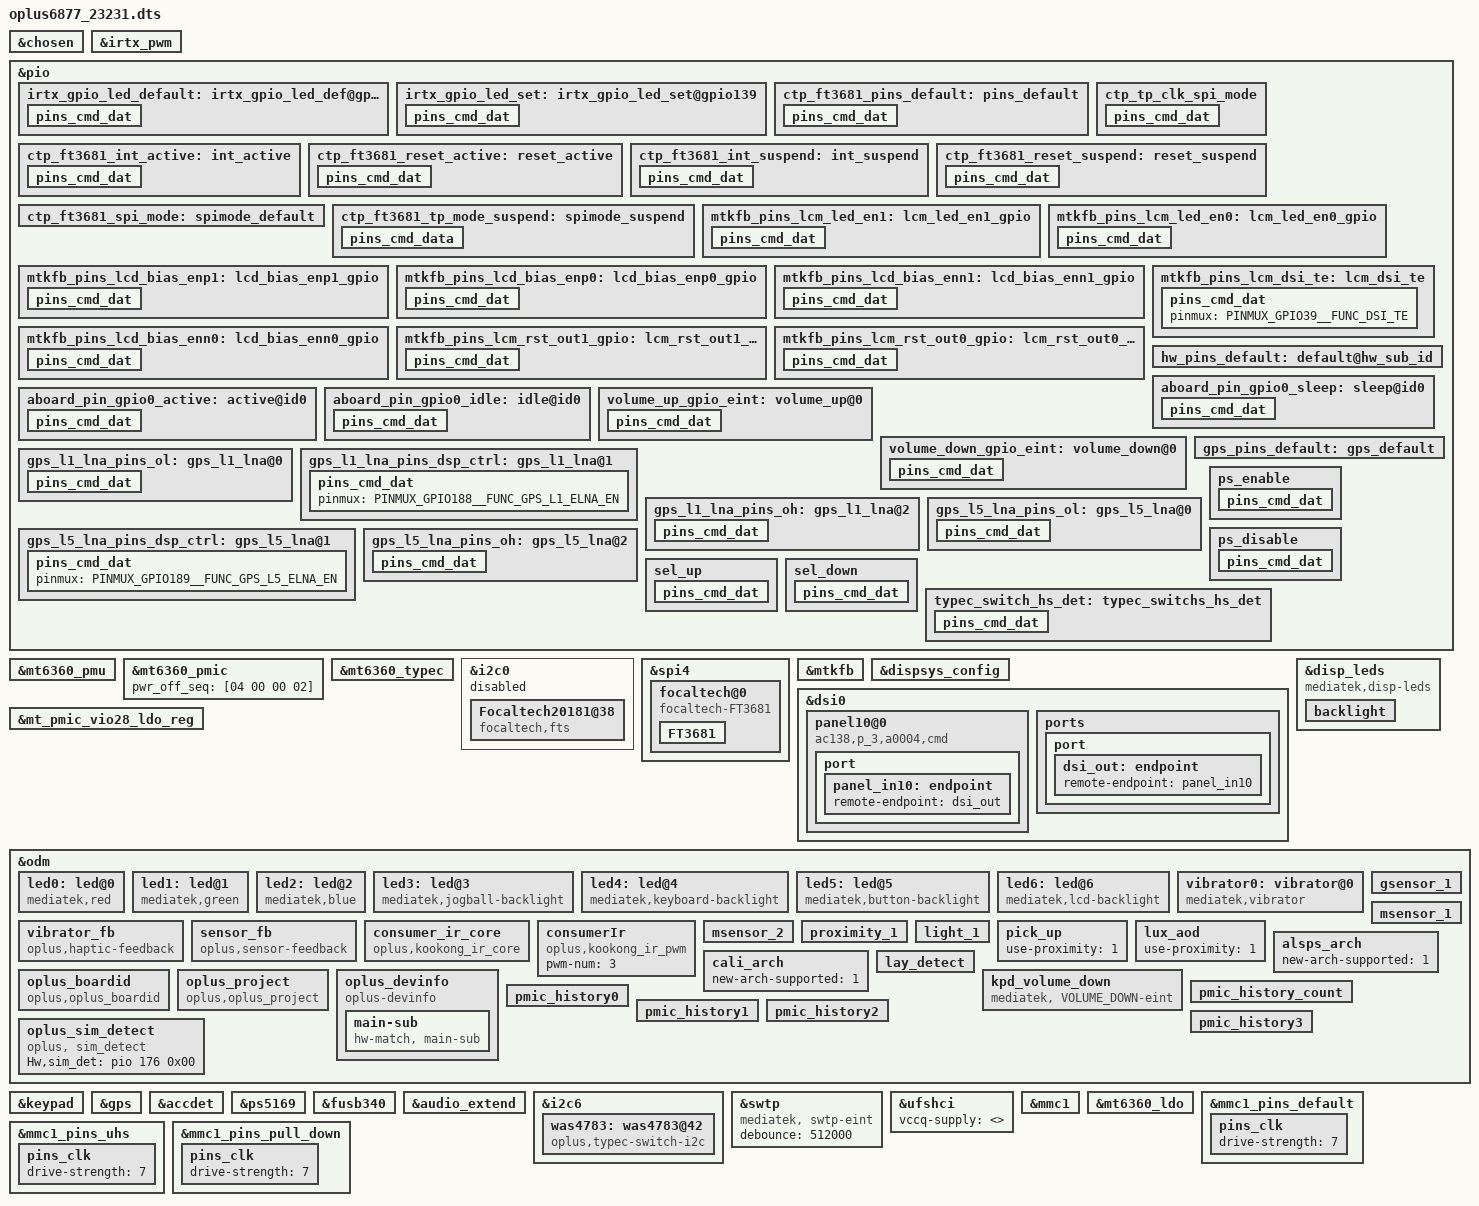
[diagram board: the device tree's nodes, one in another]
// SPDX-License-Identifier: GPL-2.0
/*
 * Copyright (c) 2021 MediaTek Inc.
 */

/dts-v1/;
/plugin/;
#include <dt-bindings/interrupt-controller/irq.h>
#include <dt-bindings/interrupt-controller/arm-gic.h>
#include <dt-bindings/pinctrl/mt6877-pinfunc.h>
#include <dt-bindings/mmc/mt6877-msdc.h>

/* #ifdef CONFIG_UFF_FINGERPRINT */
#include "mediatek/oplus_uff_23231.dtsi"
/* #endif CONFIG_UFF_FINGERPRINT */

/* chosen */
&chosen {
	atag,videolfb-fb_base_l = <0x7e605000>;
	atag,videolfb-fb_base_h = <0x0>;
	atag,videolfb-islcmfound = <1>;
	atag,videolfb-islcm_inited = <0>;
	atag,videolfb-fps= <6000>;
	atag,videolfb-vramSize= <0x1be0000>;
	atag,videolfb-lcmname=
		"td4330_fhdp_dsi_cmd_auo_rt4831_drv";
};

/* IRTX GPIO Start */
&irtx_pwm {
	pinctrl-names = "irtx_gpio_led_default", "irtx_gpio_led_set";
	pinctrl-0 = <&irtx_gpio_led_default>;
	pinctrl-1 = <&irtx_gpio_led_set>;
	status = "okay";
};
&pio {
	/* IRTX GPIO Settings -Start */
	/* default: GPIO0, output, high */
	irtx_gpio_led_default:irtx_gpio_led_def@gpio139 {
		pins_cmd_dat {
			pinmux = <PINMUX_GPIO139__FUNC_GPIO139>;
			slew-rate = <1>;
			bias-disable;
			output-low;
			input-schmitt-enable = <0>;
		};
	};

	irtx_gpio_led_set:irtx_gpio_led_set@gpio139 {
		pins_cmd_dat {
			pinmux = <PINMUX_GPIO139__FUNC_PWM_1>;
			slew-rate = <1>;
			output-high;
		};
	};
}; /* IRTX GPIO Settings -End */

&mt6360_pmu {
	mt6360,intr_gpio_num = <4>; /* direct defined GPIO num */
	mt6360,intr_gpio = <&pio 4 0x0>;
};

&mt6360_pmic {
	pwr_off_seq = [04 00 00 02];
};

&mt6360_typec {
	mt6360pd,intr_gpio_num = <5>; /* direct defined GPIO num */
	mt6360pd,intr_gpio = <&pio 5 0x0>;
};

/*touch start*/

&i2c0 {
	status = "disable";
		Focaltech20181@38 {
		compatible = "focaltech,fts";
		reg = <0x38>;
		chip-name = "FT3518";

		/* Interrupt && Irq-gpio */
		interrupt-parent = <&pio>;
		interrupts = <14 0x2002>;

		/* Power Config */
		vdd_2v8-supply  = <&mt_pmic_vtp_ldo_reg>;
		vdd_2v8_volt = <3000000>;

		/* Other HW Resource */
		irq-gpio = <&pio 14 0x2002>;
		reset-gpio = <&pio 15 0x1>;
		//pinctrl-names = "default";
		//pinctrl-0 = <&ctp_ts_int_active &ctp_ts_reset_active>;

		vid_len = <2>;
		tp_type = <8>;
		// type of tp_dev ,TP-SAMSUNG = 8;
		platform_support_project = <23231>;
		platform_support_project_dir = <23231>;
		platform_support_project_commandline = "default_commandline", "default_commandline", "default_commandline";

		touchpanel,max-num-support = <10>;
		touchpanel,tx-rx-num = <16 34>;
		touchpanel,panel-coords = <4320 9600>;
		touchpanel,display-coords = <1080 2400>;
		touchpanel,touchmajor-limit = <0 216>;
		touchpanel,report-rate = <120 180>;
		touchpanel,smooth-level = <255 2 15 25 45 60>;
		touchpanel,smooth-level-charging = <255 15 20 25 45 60>;
		touchpanel,sensitive-level = <255 20 16 13 10 5>;
		touchpanel,single-optimized-time = <8>;

		//prevention,dead_area_width = <20 20>;
		//prevention,condition_area_width = <60 60 160 160>;
		//prevention,eli_area_width = <240 1000 1200 240>;

		/* SW Support Feature Control */
		black_gesture_support;
		//black_gesture_indep_support;
		fw_edge_limit_support;
		pressure_report_support;
		charger_pump_support;
		game_switch_support;
		smart_gesture_support;
		fw_update_app_support;
		fingerprint_underscreen_support;
		headset_pump_support;
		//irq_need_dev_resume_ok;
		health_monitor_v2_support;
		high_resolution_support;
		//esd_handle_support;
		lcd_tp_refresh_support;
		exception_upload_support;
		/*
		 *Virtual Key Config:
		 *1:touchpanel,button-type: <virtualkey_type  supportted_button-map>
		 *virtualkey_type:
		 *Type 1: using board_properties
		 *Type 2: using same IC (button zone&& touch zone are seprate)
		 *Type 3: using diffrent IC (button zone&& touch zone are seprate)
		 *Type 4: No need of virtual key process
		 *supportted_button-map:select|menu|home|back
		 *
		 *2:touchpanel,button-map
		 *type (X1,Y1)(X2,Y2)(X3,Y3)(Width_X,Hight_Y)--Only when button-type is 0
		 */
		touchpanel,button-type = <4>;
		touchpanel.button-TRx = <0 0>;
	};
};

&spi4 {
	status = "okay";
	#address-cells = <1>;
	#size-cells = <0>;

	focaltech@0{
		compatible = "focaltech-FT3681";
		reg = <0x0>;
		chip-name = "FT3681";
		status = "okay";
		spi-max-frequency = <12000000>;
		/* Interrupt && Irq-gpio */
		interrupt-parent = <&pio>;
		interrupts = <14 0x2002>;

		/* Power Config */

		vdd_2v8-supply  = <&mt_pmic_vtp_ldo_reg>;
		vdd_2v8_volt = <3000000>;
		vcc_1v8-supply  = <&mt_pmic_vfp_ldo_reg>;
		vcc_1v8_volt = <1800000>;


		/* Other HW Resource */

		irq-gpio = <&pio 14 0x2002>;
		reset-gpio = <&pio 15 0x1>;

		pinctrl-names = "default",  "ft3681_int_active",
			"ft3681_reset_active", "ft3681_int_suspend",
			"ft3681_reset_suspend", "ft3681_spi_mode",
			"ft3681_tp_mode_suspend";
		pinctrl-0 = <&ctp_ft3681_pins_default &ctp_tp_clk_spi_mode>;
		pinctrl-1 = <&ctp_ft3681_int_active>;
		pinctrl-2 = <&ctp_ft3681_reset_active>;
		pinctrl-3 = <&ctp_ft3681_int_suspend>;
		pinctrl-4 = <&ctp_ft3681_reset_suspend>;
		pinctrl-5 = <&ctp_ft3681_spi_mode>;
		pinctrl-6 = <&ctp_ft3681_tp_mode_suspend>;

		touchpanel,max-num-support = <10>;
		touchpanel,tx-rx-num = <16 36>;
		earsense,tx-rx-num = <17 18>;
		touchpanel,panel-coords = <8640 19296>;
		touchpanel,display-coords = <1080 2412>;
		touchpanel,touchmajor-limit = <128 216>;
		touchpanel,elimination-range = <20 200 200>;
		//touchpanel,int-mode = <1>; /*0: interrupt and disable, 1:interrupt and not disable*/
		touchpanel,smooth-level = <0 110 115 120 140 155>;
		touchpanel,smooth-level-charging = <0 110 115 120 140 155>;
		touchpanel,sensitive-level = <0 19 16 12 11 10>;
		touchpanel,tp-index = <0>;
		touchpanel,high-frame-rate-time = <60>;
		disable_suspend_irq_handler_support;

		vid_len = <2>;
		//firmware_name = "0xAB30500";
		tp_type = <3>; /* panel-BOE*/
		platform_support_project = <23231>;
		platform_support_project_dir = <23231>;
		platform_support_project_commandline = "default_commandline";

		prevention,curved_screen_V2;
		prevention,grip_disable_level = <6>;
		prevention,updelay_time_ms = <30>;
		prevention,makeup_cnt_weight = <4 1 2 2 2>;
		prevention,large_corner_range = <960 2400>;
		prevention,large_corner_judge_condition = <500 300 800 6 6>;
		prevention,trx_reject_condition = <8 7 7>;
		prevention,trx_strict_reject_condition = <7 6 6>;
		prevention,large_judge_time_ms = <500 50 30>;
		prevention,large_exit_condition = <15 12 2>;
		prevention,single_channel_width = <256 256>;
		prevention,normal_tap_condition = <10 300>;
		prevention,long_edge_condition = <230 100 180 80>;
		prevention,long_strict_edge_condition = <170 80>;
		prevention,long_fingerhold_condition = <50 6 4 4>;
		prevention,short_edge_condition = <230 100 180 80>;
		prevention,short_strict_edge_condition = <160 60>;
		prevention,large_strict_exit_condition = <5 5>;
		prevention,top_corner_config = <400 1200 380>;
		prevention,edge_swipe_config = <240 800>;

		prevention,curved_screen_V4;
		prevention,long_eliminate_point_type = <2 8640 6640 210 19296 300 1>;
		prevention,long_fingerhold_condition2 = <560 1600 0 0>;
		prevention,top_corner_config2 =<3 80 420 1200 0>;
		prevention,hor_long_top_corner_config =<240 1600 0 0>;
		prevention,top_middle_config =<8640 800 800 0>;
		prevention,corner_eliminate_point_type =<0 960 1600 1>;
		prevention,finger_hold_differ_size = <1 0 360 300>;
		prevention,finger_hold_max_rx_exit_distance = <5 350 1700>;
		prevention,max_rx_exit_distance = <1 5 90 350 1400>;
		prevention,dynamic_finger_hold_exit_distance = <1 290 1700 390>;
		prevention,edge_sliding_matched_support = <1 250 3 0>;

		//grip v4.2 reclining mode
		prevention,reclining_mode_support = <1>;
		prevention,long_eliminate_point_type_recli = <2 8640 6640 210 19296 200 1>;
		prevention,finger_hold_differ_size_recli = <1 0 360 300>;
		prevention,finger_hold_max_rx_exit_distance_recli = <5 350 1700>;
		prevention,max_rx_exit_distance_recli = <1 5 90 350 1400>;
		prevention,dynamic_finger_hold_exit_distance_recli = <1 290 1700 390>;
		prevention,edge_sliding_matched_support_recli = <1 200 3 0>;
		prevention,long_edge_condition_recli = <120 100 150 100>;

		/* SW Support Feature Control */
		//esd_handle_support;
		//register-is-16bit;
		//wireless_charger_support;
		headset_pump_support;
		//fw_edge_limit_support;

		health_monitor_v2_support;
		black_gesture_support;
		charger_pump_support;
		lcd_tp_refresh_support;
		fw_update_app_support;
		smart_gesture_support;
		game_switch_support;
		report_flow_unlock_support;
		kernel_grip_support;
		fingerprint_underscreen_support;
		pressure_report_support;
		touchpanel,single-optimized-time = <8>;
		//report_rate_white_list_support;
		auto_test_force_pass_support;
		snr_read_support;
		//high_resolution_support;
		screenoff_fingerprint_info_support;
		irq_need_dev_resume_ok;
		sportify_aod_gesture_support;
		black_gesture_indep_support;
		thermal_detect_support;
		exception_upload_support;
		tp_data_record_support;
		palm_to_sleep_support;

		/*
		 *Virtual Key Config:
		 *1:touchpanel,button-type: <virtualkey_type  supportted_button-map>
		 *virtualkey_type:
		 *Type 1: using board_properties
		 *Type 2: using same IC (button zone&& touch zone are seprate)
		 *Type 3: using diffrent IC (button zone&& touch zone are seprate)
		 *Type 4: No need of virtual key process
		 *supportted_button-map:select|menu|home|back
		 *
		 *2:touchpanel,button-map
		 *type (X1,Y1)(X2,Y2)(X3,Y3)(Width_X,Hight_Y)--Only when button-type is 0
		 */
		touchpanel,button-type = <4>;
		touchpanel.button-TRx = <0 0>;

		FT3681 {
			switch_report_rate;
			report_rate_default = <60>;
			report_rate_game_value = <0x02>;
		};
	};
};


&pio {
	ctp_ft3681_pins_default: pins_default {
		pins_cmd_dat {
			pinmux = <PINMUX_GPIO12__FUNC_SPI4_MI>,
				<PINMUX_GPIO13__FUNC_SPI4_MO>,
				<PINMUX_GPIO65__FUNC_SPI4_CSB>;
			drive-strength = <2>;
		};
	};
	ctp_tp_clk_spi_mode:ctp_tp_clk_spi_mode{
		pins_cmd_dat {
			pinmux = <PINMUX_GPIO64__FUNC_SPI4_CLK>;
			mediatek,drive-strength-adv = <0>;/*EH[2:0]*/
			drive-strength = <2>;
		};
	};
	ctp_ft3681_int_active: int_active {
		pins_cmd_dat {
			pinmux = <PINMUX_GPIO14__FUNC_GPIO14>;
			input-enable;
		};
	};
	ctp_ft3681_reset_active: reset_active {
		pins_cmd_dat {
			pinmux = <PINMUX_GPIO15__FUNC_GPIO15>;
			output-high;
		};
	};
	ctp_ft3681_int_suspend: int_suspend {
		pins_cmd_dat {
			pinmux = <PINMUX_GPIO14__FUNC_GPIO14>;
			output-low;
		};
	};
	ctp_ft3681_reset_suspend: reset_suspend {
		pins_cmd_dat {
			pinmux = <PINMUX_GPIO15__FUNC_GPIO15>;
			output-low;
		};
	};
	ctp_ft3681_spi_mode: spimode_default {
	};
	ctp_ft3681_tp_mode_suspend: spimode_suspend {
		pins_cmd_data {
			pinmux = <PINMUX_GPIO64__FUNC_GPIO64>,
					<PINMUX_GPIO65__FUNC_GPIO65>,
					<PINMUX_GPIO12__FUNC_GPIO12>,
					<PINMUX_GPIO13__FUNC_GPIO13>,
					<PINMUX_GPIO14__FUNC_GPIO14>,
					<PINMUX_GPIO15__FUNC_GPIO15>;

			bias-disable;
			output-low;
		};
	};
};

&pio {
	mtkfb_pins_lcm_led_en1: lcm_led_en1_gpio {
		pins_cmd_dat {
			pinmux = <PINMUX_GPIO107__FUNC_GPIO107>;
			slew-rate = <1>;
			output-high;
		};
	};

	mtkfb_pins_lcm_led_en0: lcm_led_en0_gpio {
		pins_cmd_dat {
			pinmux = <PINMUX_GPIO107__FUNC_GPIO107>;
			slew-rate = <1>;
			output-low;
		};
	};

	mtkfb_pins_lcd_bias_enp1: lcd_bias_enp1_gpio {
		pins_cmd_dat {
			pinmux = <PINMUX_GPIO108__FUNC_GPIO108>;
			slew-rate = <1>;
			output-high;
		};
	};

	mtkfb_pins_lcd_bias_enp0: lcd_bias_enp0_gpio {
		pins_cmd_dat {
			pinmux = <PINMUX_GPIO108__FUNC_GPIO108>;
			slew-rate = <1>;
			output-low;
		};
	};

	mtkfb_pins_lcd_bias_enn1: lcd_bias_enn1_gpio {
		pins_cmd_dat {
			pinmux = <PINMUX_GPIO111__FUNC_GPIO111>;
			slew-rate = <1>;
			output-high;
		};
	};

	mtkfb_pins_lcd_bias_enn0: lcd_bias_enn0_gpio {
		pins_cmd_dat {
			pinmux = <PINMUX_GPIO111__FUNC_GPIO111>;
			slew-rate = <1>;
			output-low;
		};
	};

	mtkfb_pins_lcm_rst_out1_gpio: lcm_rst_out1_gpio {
		pins_cmd_dat {
			pinmux = <PINMUX_GPIO40__FUNC_GPIO40>;
			slew-rate = <1>;
			output-high;
		};
	};

	mtkfb_pins_lcm_rst_out0_gpio: lcm_rst_out0_gpio {
		pins_cmd_dat {
			pinmux = <PINMUX_GPIO40__FUNC_GPIO40>;
			slew-rate = <1>;
			output-low;
		};
	};
	mtkfb_pins_lcm_dsi_te: lcm_dsi_te {
		pins_cmd_dat {
			pinmux = <PINMUX_GPIO39__FUNC_DSI_TE>;
		};
	};
};

&mtkfb {
	pinctrl-names = "lcm_led_en1_gpio", "lcm_led_en0_gpio",
		"lcd_bias_enp1_gpio", "lcd_bias_enp0_gpio",
		"lcd_bias_enn1_gpio", "lcd_bias_enn0_gpio",
		"lcm_rst_out1_gpio", "lcm_rst_out0_gpio",
		"mode_te_te";
	pinctrl-0 = <&mtkfb_pins_lcm_led_en1>;
	pinctrl-1 = <&mtkfb_pins_lcm_led_en0>;
	pinctrl-2 = <&mtkfb_pins_lcd_bias_enp1>;
	pinctrl-3 = <&mtkfb_pins_lcd_bias_enp0>;
	pinctrl-4 = <&mtkfb_pins_lcd_bias_enn1>;
	pinctrl-5 = <&mtkfb_pins_lcd_bias_enn0>;
	pinctrl-6 = <&mtkfb_pins_lcm_rst_out1_gpio>;
	pinctrl-7 = <&mtkfb_pins_lcm_rst_out0_gpio>;
	pinctrl-8 = <&mtkfb_pins_lcm_dsi_te>;
	status = "okay";
};
&dispsys_config {
	pinctrl-names =
		"lcm_rst_out1_gpio", "lcm_rst_out0_gpio",
		"mode_te_te";
	pinctrl-0 = <&mtkfb_pins_lcm_rst_out1_gpio>;
	pinctrl-1 = <&mtkfb_pins_lcm_rst_out0_gpio>;
	pinctrl-2 = <&mtkfb_pins_lcm_dsi_te>;
	status = "okay";
	helper-value = <0>, /*MTK_DRM_OPT_STAGE*/
		<1>, /*MTK_DRM_OPT_USE_CMDQ*/
		<1>, /*MTK_DRM_OPT_USE_M4U*/
		<0>, /*MTK_DRM_OPT_SODI_SUPPORT*/
		<1>, /*MTK_DRM_OPT_IDLE_MGR*/
		<0>, /*MTK_DRM_OPT_IDLEMGR_SWTCH_DECOUPLE*/
		<1>, /*MTK_DRM_OPT_IDLEMGR_BY_REPAINT*/
		<0>, /*MTK_DRM_OPT_IDLEMGR_ENTER_ULPS*/
		<0>, /*MTK_DRM_OPT_IDLEMGR_KEEP_LP11*/
		<0>, /*MTK_DRM_OPT_DYNAMIC_RDMA_GOLDEN_SETTING*/
		<1>, /*MTK_DRM_OPT_IDLEMGR_DISABLE_ROUTINE_IRQ*/
		<0>, /*MTK_DRM_OPT_MET_LOG*/
		<1>, /*MTK_DRM_OPT_USE_PQ*/
		<1>, /*MTK_DRM_OPT_ESD_CHECK_RECOVERY*/
		<1>, /*MTK_DRM_OPT_ESD_CHECK_SWITCH*/
		<1>, /*MTK_DRM_OPT_PRESENT_FENCE*/
		<0>, /*MTK_DRM_OPT_RDMA_UNDERFLOW_AEE*/
		<1>, /*MTK_DRM_OPT_DSI_UNDERRUN_AEE*/
		<1>, /*MTK_DRM_OPT_HRT*/
		<1>, /*MTK_DRM_OPT_HRT_MODE*/
		<0>, /*MTK_DRM_OPT_DELAYED_TRIGGER*/
		<1>, /*MTK_DRM_OPT_OVL_EXT_LAYER*/
		<0>, /*MTK_DRM_OPT_AOD*/
		<1>, /*MTK_DRM_OPT_RPO*/
		<0>, /*MTK_DRM_OPT_DUAL_PIPE*/
		<0>, /*MTK_DRM_OPT_DC_BY_HRT*/
		<0>, /*MTK_DRM_OPT_OVL_WCG*/
		<0>, /*MTK_DRM_OPT_OVL_SBCH*/
		<1>, /*MTK_DRM_OPT_COMMIT_NO_WAIT_VBLANK*/
		<0>, /*MTK_DRM_OPT_MET*/
		<0>, /*MTK_DRM_OPT_REG_PARSER_RAW_DUMP*/
		<0>, /*MTK_DRM_OPT_VP_PQ*/
		<0>, /*MTK_DRM_OPT_GAME_PQ*/
		<0>, /*MTK_DRM_OPT_MMPATH*/
		<1>, /*MTK_DRM_OPT_HBM*/
		<0>, /*MTK_DRM_OPT_VDS_PATH_SWITCH*/
		<0>, /*MTK_DRM_OPT_LAYER_REC*/
		<0>, /*MTK_DRM_OPT_CLEAR_LAYER*/
		<1>, /*MTK_DRM_OPT_LFR*/
		<1>; /*MTK_DRM_OPT_DYN_MIPI_CHANGE*/
};

&dsi0 {
	status = "okay";
	#address-cells = <1>;
	#size-cells = <0>;
	panel10@0 {
		compatible = "ac138,p_3,a0004,cmd";
		reg = <0>;
		reset-gpios = <&pio 40 0>;
		pinctrl-names = "default";
		port {
			panel_in10: endpoint {
				remote-endpoint = <&dsi_out>;
			};
		};
	};
	ports {
		port {
			dsi_out: endpoint {
				remote-endpoint = <&panel_in10>;
			};
		};
	};
};

&disp_leds {
	compatible = "mediatek,disp-leds";
	backlight {
		label = "lcd-backlight";
		max-brightness = <4095>;
		led-bits = <12>;
		trans-bits = <12>;
		default-state = "on";
	};
};

&mt_pmic_vio28_ldo_reg {
	regulator-name = "vio28";
	regulator-min-microvolt = <3000000>;
	regulator-max-microvolt = <3000000>;
	regulator-enable-ramp-delay = <0>;
};

&odm {
	led0:led@0 {
		compatible = "mediatek,red";
		led_mode = <0>;
		data = <1>;
		pwm_config = <0 0 0 0 0>;
	};
	led1:led@1 {
		compatible = "mediatek,green";
		led_mode = <0>;
		data = <1>;
		pwm_config = <0 0 0 0 0>;
	};
	led2:led@2 {
		compatible = "mediatek,blue";
		led_mode = <0>;
		data = <1>;
		pwm_config = <0 0 0 0 0>;
	};
	led3:led@3 {
		compatible = "mediatek,jogball-backlight";
		led_mode = <0>;
		data = <1>;
		pwm_config = <0 0 0 0 0>;
	};
	led4:led@4 {
		compatible = "mediatek,keyboard-backlight";
		led_mode = <0>;
		data = <1>;
		pwm_config = <0 0 0 0 0>;
	};
	led5:led@5 {
		compatible = "mediatek,button-backlight";
		led_mode = <0>;
		data = <1>;
		pwm_config = <0 0 0 0 0>;
	};
	led6:led@6 {
		compatible = "mediatek,lcd-backlight";
		led_mode = <4>;
		data = <1>;
		pwm_config = <0 1 0 0 0>;
	};
	vibrator0:vibrator@0 {
		compatible = "mediatek,vibrator";
		vib_timer = <25>;
		vib_limit = <9>;
		vib_vol= <9>;
	};
	vibrator_fb:vibrator_fb {
		compatible = "oplus,haptic-feedback";
	};
/* sensor start */
	sensor_fb: sensor_fb {
		compatible = "oplus,sensor-feedback";
	};
	consumer_ir_core: consumer_ir_core {
		compatible = "oplus,kookong_ir_core";
		status = "okay";
		vdd-type = <1>;
		vdd-min-vol = <3060>;
		vdd-max-vol = <3060>;
	};
	consumerIr: consumerIr {
		compatible = "oplus,kookong_ir_pwm";
		status = "okay";
		pwm-num = <3>;
	};
	/*
	enum {
		LIS3DH,
		LSM6DS3,
		BMI160,
		LIS2HH12,
		LSM6DSM,
		BMI2XY,
		LSM6DSO,
		BMA4XY,
		SC7A20,
		ICM4X6XX,
	};
	*/
	gsensor_1: gsensor_1 {
		status = "okay";
		sensor_name = <5>;//BMI2XY
		device_name = "bmi2xy";
		i2c_num = <2>;
		i2c_addr = <0>;
		direction = <7>;
		eint_num = <1>;
		gyro_cali_version= <2>;
		acc_cali_range= <300 300 300>; //300mg
	};
	/*
	enum {
		AKM09911,
		MMC3530,
		MMC5603,
		MXG4300,
	};
	*/
	msensor_1: msensor_1 {
		status = "okay";
		sensor_name = <3>;//MXG4300
		i2c_num = <0>;
		i2c_addr = <12>;
		direction = <1>;
		eint_num = <0>;
		soft-mag-parameter = <9366 0 1038 0 588 0 1163 0 9813 0 434 1 223 1 256 1 10297 0>;
	};
	msensor_2: msensor_2 {
		status = "okay";
		sensor_name = <2>;//MMC5603
		i2c_num = <0>;
		i2c_addr = <48>;
		direction = <1>;
		eint_num = <0>;
		soft-mag-parameter = <9946 0 1022 0 77 0 905 0 10841 0 38 1 202 0 857 1 11559 0>;
	};
	/*
	enum {
		TMD2725,
		APSD9922,
		STK3335,
		STK3331,
		STK2232,
		TCS3701,
		STK32600,
	};
	*/
	proximity_1: proximity_1 {
		status = "okay";
		sensor_name = <6>;//STK32600
		i2c_num = <0>;
		i2c_addr = <72>;
		direction = <4>;
		eint_num = <2>;
		low_step = <300>;
		high_step = <400>;
		low_limit = <400>;
		high_limit = <600>;
		dirty_low_step = <300>;
		dirty_high_step = <400>;
		ps_dirty_limit = <1800>;
		ps_ir_limit = <2000>;
		ps_adjust_min = <0>;
		ps_adjust_max = <1850>;
		sampling_count = <5>;
		step_max = <400>;
		step_min = <100>;
		step_div = <2000>;
		anti_shake_delta = <70>;
		dynamic_cali_max = <2000>;
		raw2offset_radio = <1000>;
		offset_max = <60000>;
		offset_range_min = <0>;
		offset_range_max = <65535>;
		force_cali_limit = <2000>;
		cali_jitter_limit = <30>;
		cal_offset_margin = <3000>;
		sensor-reg = <0x03 0x28 0x01 0x36 0x81 0xa0>;
	};
	light_1: light_1 {
		status = "okay";
		sensor_name = <6>;//STK32600
		i2c_num = <0>;
		i2c_addr = <72>;
		direction = <4>;
		eint_num = <2>;
		als_buffer_length =<8>;
		als_ratio = <180>;
		als_type = <2>;//<1-normal;2-under screen;3-normal needed compensation>
		device_name = "stk32600";
		use_als_c2 = <1>;
	};
	pick_up: pick_up {
		status = "okay";
		use-proximity = <1>;
	};
	lux_aod: lux_aod {
		status = "okay";
		use-proximity = <1>;
	};
	alsps_arch: alsps_arch {
		status = "okay";
		new-arch-supported = <1>;
	};
	cali_arch: cali_arch {
		status = "okay";
		new-arch-supported = <1>;
	};
	lay_detect: lay_detect{
		status = "okay";
		max_angel = <90>;
		min_angel = <30>;
		lay_in_time = <10>;
		lay_out_time = <3>;
	};
/* sensor end */

	oplus_boardid:oplus_boardid {
		compatible = "oplus,oplus_boardid";
		oplus_boardid,dtsino="23231";//only one u32
		oplus_boardid,pcbmask="0x0007";//all mask 0xffff
	};

/* OPLUS_BUG_STABILITY oplus project start */
	oplus_project:oplus_project {
		compatible = "oplus,oplus_project";
	};
	oplus_devinfo:oplus_devinfo {
		compatible = "oplus-devinfo";

		pinctrl-names = "default", "aboard_gpio0_sleep", "aboard_gpio0_active", "aboard_gpio0_idle";
		pinctrl-0 = <&hw_pins_default>;
		pinctrl-1 = <&aboard_pin_gpio0_sleep>;
		pinctrl-2 = <&aboard_pin_gpio0_active>;
		pinctrl-3 = <&aboard_pin_gpio0_idle>;
		main-sub {
			use_tristate_gpio;
            compatible = "hw-match, main-sub";
			aboard-gpio0 = <&pio 121 0x00>;
			aboard-patterns = <0>;
			/*main board*/
			match-projects = <23231>;
		};
	};

/* OPLUS_BUG_STABILITY oplus project end */

	kpd_volume_down:kpd_volume_down {
			compatible = "mediatek, VOLUME_DOWN-eint";
			interrupt-parent = <&pio>;
			interrupts = <29 IRQ_TYPE_EDGE_FALLING 29 0>;/*TRQ num 29 is linked with gpio29 (mt6877)*/
			debounce = <32000>;
			status = "okay";
	};

	pmic_history_count:pmic_history_count {
	};
	pmic_history0:pmic_history0 {
	};
	pmic_history1:pmic_history1 {
	};
	pmic_history2:pmic_history2 {
	};
	pmic_history3:pmic_history3 {
	};

};

&odm {
/* Add for sim detect */
    oplus_sim_detect {
        compatible = "oplus, sim_detect";
        Hw,sim_det = <&pio 176 0x00>;
    };
};

&pio {
        hw_pins_default:default@hw_sub_id {
        };

        aboard_pin_gpio0_sleep:sleep@id0 {
                pins_cmd_dat {
                        pinmux = <PINMUX_GPIO121__FUNC_GPIO121>;
                        slew-rate = <0>;
                        bias-pull-down;
                        input-enable;
                };
        };

        aboard_pin_gpio0_active:active@id0 {
                pins_cmd_dat {
                        pinmux = <PINMUX_GPIO121__FUNC_GPIO121>;
                        slew-rate = <0>;
                        bias-pull-up;
                        input-enable;
                };
        };

        aboard_pin_gpio0_idle:idle@id0 {
                pins_cmd_dat {
                        pinmux = <PINMUX_GPIO121__FUNC_GPIO121>;
                        slew-rate = <0>;
                        bias-disable;
                        input-enable;
                };
        };
};

&keypad {
        keypad,volume-up        = <&pio 120 0x00>;
        keypad,volume-down      = <&pio 29 0x00>;
        pinctrl-names = "volume_up_as_int", "volume_down_as_int";
        pinctrl-0 = <&volume_up_gpio_eint>;
        pinctrl-1 = <&volume_down_gpio_eint>;
        status = "okay";
};
&pio {
        volume_up_gpio_eint:volume_up@0{
                pins_cmd_dat {
                        pinmux = <PINMUX_GPIO120__FUNC_GPIO120>;
                        slew-rate = <0>;  /*direction 0:in, 1:out*/
                        input-enable;
                };
        };

        volume_down_gpio_eint:volume_down@0{
                pins_cmd_dat {
                        pinmux = <PINMUX_GPIO29__FUNC_GPIO29>;
                        slew-rate = <0>;  /*direction 0:in, 1:out*/
                        input-enable;
                };
        };
};

/* GPS GPIO standardization start */
&pio {
	gps_pins_default: gps_default {
	};
	gps_l1_lna_pins_ol: gps_l1_lna@0 {
		pins_cmd_dat {
			pinmux = <PINMUX_GPIO188__FUNC_GPIO188>;
			output-low;
		};
	};
	gps_l1_lna_pins_dsp_ctrl: gps_l1_lna@1 {
		pins_cmd_dat {
			pinmux = <PINMUX_GPIO188__FUNC_GPS_L1_ELNA_EN>;
		};
	};
	gps_l1_lna_pins_oh: gps_l1_lna@2 {
		pins_cmd_dat {
			pinmux = <PINMUX_GPIO188__FUNC_GPIO188>;
			output-high;
		};
	};
	gps_l5_lna_pins_ol: gps_l5_lna@0 {
		pins_cmd_dat {
			pinmux = <PINMUX_GPIO189__FUNC_GPIO189>;
			output-low;
		};
	};
	gps_l5_lna_pins_dsp_ctrl: gps_l5_lna@1 {
		pins_cmd_dat {
			pinmux = <PINMUX_GPIO189__FUNC_GPS_L5_ELNA_EN>;
		};
	};
	gps_l5_lna_pins_oh: gps_l5_lna@2 {
		pins_cmd_dat {
			pinmux = <PINMUX_GPIO189__FUNC_GPIO189>;
			output-high;
		};
	};
};
&gps {
	pinctrl-names = "default",
		"gps_l1_lna_disable",
		"gps_l1_lna_dsp_ctrl",
		"gps_l1_lna_enable",
		"gps_l5_lna_disable",
		"gps_l5_lna_dsp_ctrl",
		"gps_l5_lna_enable";
	pinctrl-0 = <&gps_pins_default>;
	pinctrl-1 = <&gps_l1_lna_pins_ol>;
	pinctrl-2 = <&gps_l1_lna_pins_dsp_ctrl>;
	pinctrl-3 = <&gps_l1_lna_pins_oh>;
	pinctrl-4 = <&gps_l5_lna_pins_ol>;
	pinctrl-5 = <&gps_l5_lna_pins_dsp_ctrl>;
	pinctrl-6 = <&gps_l5_lna_pins_oh>;
	status = "okay";
};
/* GPS GPIO standardization end */

&accdet {
	/* accdet micbias voltage: 0x09:2.85v 0x08:2.8v 0x07,
	 * 2.7v;0x05,2.5v;0x02,1.9v
	 */
	accdet-mic-vol = <8>;
	/* accdet pwm_width, pwm_thresh, fall_delay, rise_delay
	 * debounce0, debounce1, debounce3, debounce4
	 * eint pwm_width, eint pwm_thresh
	 * eint deb(debounce0, debounce1, debounce2, debounce3), inv_debounce
	 */
	headset-mode-setting = <0x500 0x500 1 0x1f0
				0x800 0x800 0x20 0x44
				0x4 0x1
				0x5 0x3 0x3 0x5 0xe>;
	accdet-plugout-debounce = <1>;
	/*1:ACC mode, 2:low cost without in bias, 6:low cost with in bias*/
	accdet-mic-mode = <2>;
	/*0--MD_MAX--UP_MAX--DW_MAX*/
	headset-three-key-threshold = <0 82 170 306>;
	//#else
	//headset-three-key-threshold = <0 80 220 400>;
	//#endif
	headset-three-key-threshold-CDD = <0 121 192 600>;
	/*0--MD_MAX--VOICE_MAX--UP_MAX--DW_MAX*/
	headset-four-key-threshold = <0 58 121 192 400>;

	/* select VTH to 2v and 500k, use internal resitance */
	eint_use_ext_res = <0>;
	status = "okay";
};

&ps5169{
	pinctrl-names = "enable", "disable";
	pinctrl-0 = <&ps_enable>;
	pinctrl-1 = <&ps_disable>;
	status = "okay";
};

&fusb340 {
	pinctrl-names = "sel_up", "sel_down";
	pinctrl-0 = <&sel_up>;
	pinctrl-1 = <&sel_down>;
	status = "okay";
};

&pio {
	ps_enable: ps_enable {
		pins_cmd_dat {
			pinmux = <PINMUX_GPIO121__FUNC_GPIO121>;
			output-high;
		};
	};

	ps_disable: ps_disable {
		pins_cmd_dat {
			pinmux = <PINMUX_GPIO121__FUNC_GPIO121>;
			output-low;
		};
	};

	sel_up: sel_up {
		pins_cmd_dat {
			pinmux = <PINMUX_GPIO6__FUNC_GPIO6>;
			output-high;
		};
	};

	sel_down: sel_down {
		pins_cmd_dat {
			pinmux = <PINMUX_GPIO6__FUNC_GPIO6>;
			output-low;
		};
	};
};

//#ifdef OPLUS_FEATURE_AUDIODRIVER
//add for type-c headset and si smartpa
&audio_extend {
	//for sipa speaker
	oplus,speaker-vendor = "sipa";
	oplus,speaker-i2s-id = <3>;
	oplus,speaker-i2s-id-in = <0>;
	oplus,speaker-codec-name = "sipa_i2c.6-006c","sipa_i2c.6-006d";
	oplus,speaker-codec-dai-name = "sia91xx-aif-6-6c","sia91xx-aif-6-6d";
};

&pio {
	typec_switch_hs_det: typec_switchs_hs_det {
		pins_cmd_dat {
			pinmux = <PINMUX_GPIO113__FUNC_GPIO113>;
			slew-rate = <1>;  /*direction 0:in, 1:out*/
			output-high;
		};
	};
};

&i2c6 {
	was4783: was4783@42 {
		 compatible = "oplus,typec-switch-i2c";
		 reg = <0x42>;
		 pinctrl-names = "default";
		 pinctrl-0 = <&typec_switch_hs_det>;
		 oplus,hs-det-gpio = <&pio 113 0>;
		 oplus,hp-bypass = <1>;
		 status = "okay";
	 };
};
//#endif /* OPLUS_FEATURE_AUDIODRIVER */

//#ifdef OPLUS_VENDOR_SWTP
&swtp {
	compatible = "mediatek, swtp-eint";
	debounce = <512000>;
};
//#endif  /*OPLUS_VENDOR_SWTP*/

&ufshci {
    vccq-supply = <>;
};

&mmc1 {
    cd-gpios = <&pio 3 0>;
    status = "okay";
    vmmc-supply = <&mt_pmic_vmch_ldo_reg>;
};

&mt6360_ldo {
    sdcard_det_en = <1>;
    sdcard_hlact = <0>;
};

&mmc1_pins_default {
    pins_clk {
        drive-strength = <7>;
    };
};

&mmc1_pins_uhs {
    pins_clk {
        drive-strength = <7>;
    };
};

&mmc1_pins_pull_down {
    pins_clk {
        drive-strength = <7>;
    };
};

#include "oplus6877_23231/cust.dtsi"
#include "mediatek/nfc/mt6877_burberry_pn560.dtsi"
#include "mediatek/cust_mt6877_oplus_charge_23231.dtsi"
#include "mediatek/cust_mt6877_camera_burberry.dtsi"
#include "mediatek/oplus6877_sia9175.dtsi"
/*End of this file, DO NOT ADD ANYTHING HERE*/

